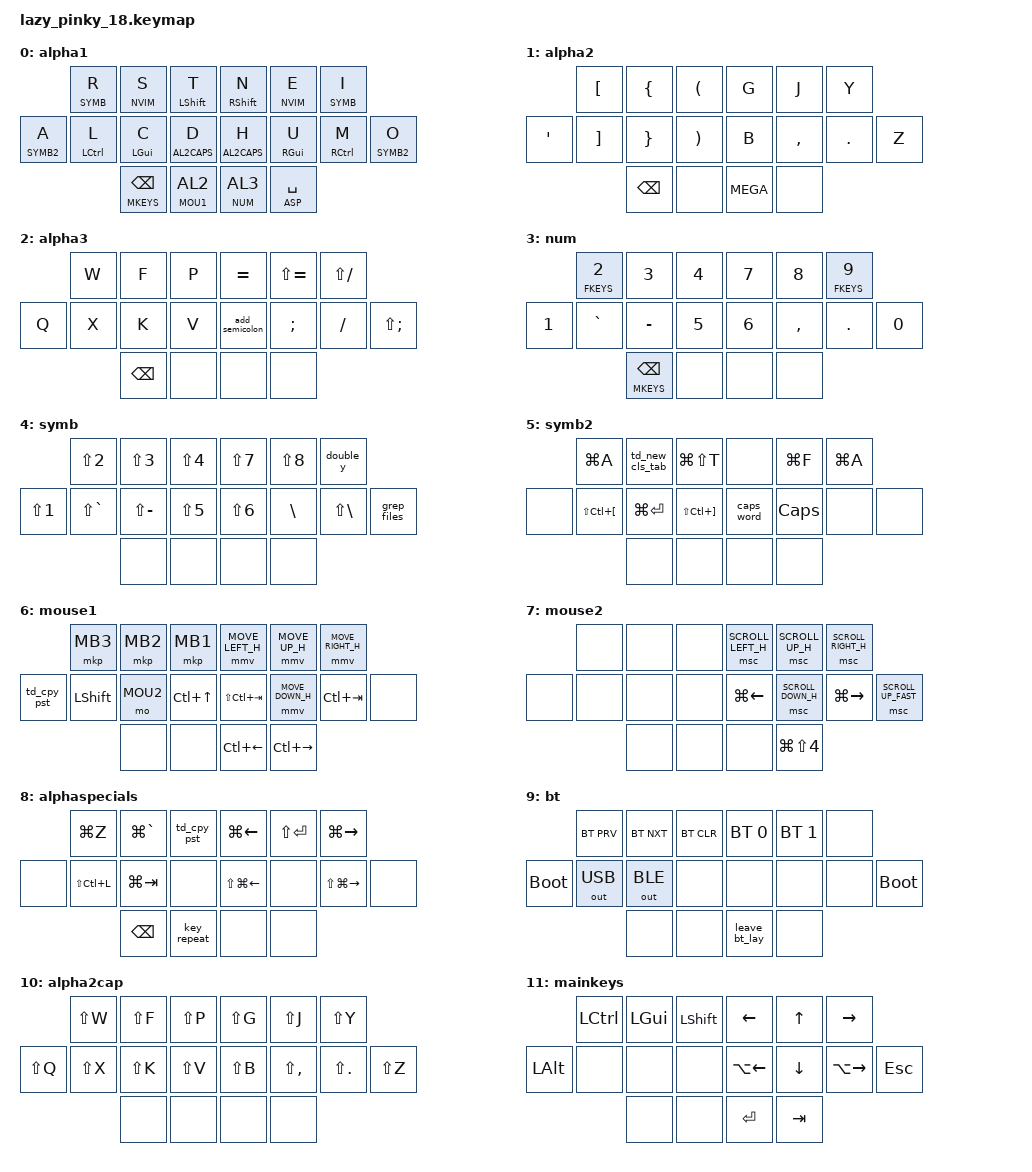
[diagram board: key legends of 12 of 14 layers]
/*
 * Copyright (c) 2020 The ZMK Contributors
 *
 * SPDX-License-Identifier: MIT
 */

#include <behaviors.dtsi>
#include <dt-bindings/zmk/keys.h>
#include <dt-bindings/zmk/bt.h>
#include <dt-bindings/zmk/mouse.h>
#include <dt-bindings/zmk/backlight.h>
#include <dt-bindings/zmk/outputs.h>

#include "mouse.dtsi"

/* Layers */
#define AL1       0
#define AL2       1
#define AL3       2
#define NUM       3
#define SYMB      4
#define SYMB2     5
#define MOU1      6
#define MOU2      7
#define ASP       8
#define BT        9
#define AL2CAPS   10
#define MKEYS     11
#define FKEYS     12
#define NVIM      13

#define MEGA LC(LG(LA(LSHIFT)))

&mt {
    tapping-term-ms = <201>;
    flavor = "tap-preferred";
 };
&sk {
     release-after-ms = <2000>;
     quick-release;
 };

/ { 
    behaviors {
        thu_l: thumb_layers_left {
            compatible = "zmk,behavior-hold-tap";
            label = "THUMB_MODS_L";
            #binding-cells = <2>;
            tapping-term-ms = <150>;
            flavor = "tap-preferred";
            quick-tap-ms = <1>;
            bindings = <&mo>, <&kp>;
        };
        thu_l_2: thumb_layers_left_2 {
            compatible = "zmk,behavior-hold-tap";
            label = "THUMB_MODS_L_2";
            #binding-cells = <2>;
            tapping-term-ms = <150>;
            flavor = "tap-preferred";
            quick-tap-ms = <1>;
            bindings = <&mo>, <&sl>;
            require-prior-idle-ms = <150>;
        };
        thu_r: thumb_layers_right {
            compatible = "zmk,behavior-hold-tap";
            label = "THUMB_MODS_R";
            #binding-cells = <2>;
            tapping-term-ms = <150>;
            flavor = "tap-preferred";
            quick-tap-ms = <1>;
            bindings = <&mo>, <&kp>;
        };
        thu_r_2: thumb_layers_right_2 {
            compatible = "zmk,behavior-hold-tap";
            label = "THUMB_MODS_R_2";
            #binding-cells = <2>;
            tapping-term-ms = <150>;
            flavor = "tap-preferred";
            quick-tap-ms = <1>;
            bindings = <&mo>, <&sl>;
            require-prior-idle-ms = <150>;
        };
        hm_l: homerow_mods_left {
            compatible = "zmk,behavior-hold-tap";
            label = "HOMEROW_MODS_L";
            #binding-cells = <2>;
            tapping-term-ms = <150>;
            quick-tap-ms = <1>;
            flavor = "tap-preferred";
            bindings = <&kp>, <&kp>;
            require-prior-idle-ms = <150>;
        };
        hm_r: homerow_mods_right {
            compatible = "zmk,behavior-hold-tap";
            label = "HOMEROW_MODS_R";
            #binding-cells = <2>;
            tapping-term-ms = <150>;
            quick-tap-ms = <1>;
            flavor = "tap-preferred";
            bindings = <&kp>, <&kp>;
            require-prior-idle-ms = <150>;
        };
        hl_l: homerow_layers_left {
            compatible = "zmk,behavior-hold-tap";
            label = "HOMEROW_LAYERS_L";
            #binding-cells = <2>;
            tapping-term-ms = <150>;
            quick-tap-ms = <1>;
            flavor = "tap-preferred";
            bindings = <&mo>, <&kp>;
            require-prior-idle-ms = <150>;
        };
        hl_r: homerow_layers_right {
            compatible = "zmk,behavior-hold-tap";
            label = "HOMEROW_LAYERS_R";
            #binding-cells = <2>;
            tapping-term-ms = <150>;
            quick-tap-ms = <1>;
            flavor = "tap-preferred";
            bindings = <&mo>, <&kp>;
            require-prior-idle-ms = <150>;
        };

        td_cpy_pst: tapdance_1 {
            compatible = "zmk,behavior-tap-dance";
            label = "TAPDANCE_CP";
            #binding-cells = <0>;
            tapping-term-ms = <200>;
            bindings = <&kp LG(C)>, <&kp LG(V)>;
        };
        td_new_cls_tab: tapdance_2 {
            compatible = "zmk,behavior-tap-dance";
            label = "TAPDANCE_NCT";
            #binding-cells = <0>;
            tapping-term-ms = <200>;
            bindings = <&kp LG(T)>, <&kp LG(W)>;
        };
        td_find_opn_lst: tapdance_3 {
            compatible = "zmk,behavior-tap-dance";
            label = "TAPDANCE_FOL";
            #binding-cells = <0>;
            tapping-term-ms = <200>;
            bindings = <&kp LG(F)>, <&kp LG(LS(T))>;
        };

      alpha2macro: behavior_macro_1 {
        compatible = "zmk,behavior-macro";
        label = "MACRO1";
        #binding-cells = <0>;
        bindings = < &sl AL2 >;
      };
      alpha3macro: behavior_macro_2 {
        compatible = "zmk,behavior-macro";
        label = "MACRO2";
        #binding-cells = <0>;
        bindings = < &sl AL3 >;
      };
      enter_bt_lay: behavior_macro_3 {
        compatible = "zmk,behavior-macro";
        label = "BT backlight ON";
        #binding-cells = <0>;
        bindings =    < &to BT >
                    , < &bl BL_OFF >
                    ;
      };
      leave_bt_lay: behavior_macro_4 {
        compatible = "zmk,behavior-macro";
        label = "BT backlight OFF";
        #binding-cells = <0>;
        bindings =    < &to AL1 >
                    , < &bl BL_ON >
                    ;
      };

      double_y: behavior_macro_7 {
        compatible = "zmk,behavior-macro";
        label = "MACRO7";
        #binding-cells = <0>;
        bindings =    < &kp Y >
                    , < &kp Y >
                    ;
      };
      grep_files: behavior_macro_8 {
        compatible = "zmk,behavior-macro";
        label = "MACRO8";
        #binding-cells = <0>;
        bindings =    < &kp SPC >
                    , < &kp SLASH >
                    ;
      };
      open_down: behavior_macro_9 {
        compatible = "zmk,behavior-macro";
        label = "MACRO9";
        #binding-cells = <0>;
        bindings =    < &kp O >
                    , < &kp DOWN >
                    ;
      };
      lazy_git: behavior_macro_10 {
        compatible = "zmk,behavior-macro";
        label = "MACRO10";
        #binding-cells = <0>;
        bindings =    < &kp SPC >
                    , < &kp G >
                    , < &kp G >
                    ;
      };
      add_semicolon: behavior_macro_11 {
        compatible = "zmk,behavior-macro";
        label = "MACRO11";
        #binding-cells = <0>;
        bindings =    < &kp ESC >
                    , < &kp LS(A) >
                    , < &kp SEMICOLON >
                    , < &kp ESC >
                    ;
      };
    };

//          0    1    2          3      4      5
//     6    7    8    9         10     11     12    13
//              14   15         16     17
    keymap {
    compatible = "zmk,keymap";

    alpha1 { bindings = <
                     &hl_l SYMB  R    &hl_l  NVIM  S        &hm_l    LSHIFT  T      &hm_r    RSHIFT  N    &hl_r  NVIM E     &hl_r SYMB  I
    &hl_l SYMB2 A    &hm_l LCTRL L    &hm_l  LGUI  C        &hl_l    AL2CAPS D      &hl_r    AL2CAPS H    &hm_r  RGUI U     &hm_r RCTRL M   &hl_r SYMB2 O
                                      &thu_l MKEYS BKSP     &thu_l_2 MOU1    AL2    &thu_r_2 NUM     AL3  &thu_r ASP  SPC
    >; };

    alpha2 { bindings = <
                        &kp LEFT_BRACKET   &kp LEFT_BRACE     &kp LEFT_PARENTHESIS    &kp G       &kp J          &kp Y
    &kp SINGLE_QUOTE    &kp RIGHT_BRACKET  &kp RIGHT_BRACE    &kp RIGHT_PARENTHESIS   &kp B       &kp COMMA      &kp DOT    &kp Z 
                                           &kp BKSP           &none                   &kp MEGA    &none
    >; };

    alpha3 { bindings = <
              &kp W     &kp F     &kp P        &kp EQUAL       &kp LS(EQUAL)    &kp LS(SLASH)
    &kp Q     &kp X     &kp K     &kp V        &add_semicolon  &kp SEMICOLON    &kp SLASH        &kp LS(SEMICOLON)
                        &kp BKSP  &none        &none        &none
    >; };

    num { bindings = <
            &hl_r FKEYS N2   &kp N3               &kp N4       &kp N7     &kp N8           &hl_r FKEYS N9
    &kp N1  &kp GRAVE        &kp MINUS            &kp N5       &kp N6     &kp COMMA        &kp DOT         &kp N0
                             &hl_l MKEYS BKSP     &none        &none      &none
    >; };

    symb { bindings = <
                &kp LS(N2)        &kp LS(N3)         &kp LS(N4)     &kp LS(N7)     &kp LS(N8)       &double_y
    &kp LS(N1)  &kp LS(GRAVE)     &kp LS(MINUS)      &kp LS(N5)     &kp LS(N6)     &kp BACKSLASH    &kp LS(BACKSLASH)       &grep_files
                                  &none              &none          &none          &none
    >; };

    symb2 { bindings = <
             &kp LG(A)                  &td_new_cls_tab    &kp LG(LS(T))                &none         &kp LG(F)      &kp LG(A)
    &none    &kp LS(LC(LEFT_BRACKET))   &kp LG(ENTER)      &kp LS(LC(RIGHT_BRACKET))    &caps_word    &kp CAPS       &none      &none
                                        &none              &none                        &none         &none
    >; };

    mouse1 { bindings = <
                  &mkp  MB3    &mkp MB2  &mkp MB1    &mmv MOVE_LEFT_H   &mmv MOVE_UP_H     &mmv MOVE_RIGHT_H
    &td_cpy_pst   &kp LSHIFT   &mo MOU2  &kp LC(UP)  &kp LS(LC(TAB))    &mmv MOVE_DOWN_H   &kp LC(TAB)        &none
                               &none     &none       &kp LC(LEFT)       &kp LC(RIGHT)
    >; };

    mouse2 { bindings = <
           &none   &none   &none   &msc SCROLL_LEFT_H   &msc SCROLL_UP_H     &msc SCROLL_RIGHT_H
    &none  &none   &none   &none   &kp LG(LEFT)         &msc SCROLL_DOWN_H   &kp LG(RIGHT)         &msc SCROLL_UP_FAST
                   &none   &none   &none                &kp LG(LS(N4))  
    >; };

    alphaspecials { bindings = <
            &kp LG(Z)       &kp LG(GRAVE)    &td_cpy_pst      &kp LG(LEFT)         &kp LS(ENTER)     &kp LG(RIGHT)
    &none   &kp LS(LC(L))   &kp LG(TAB)      &none            &kp LS(LG(LEFT))     &none             &kp LS(LG(RIGHT))   &none
                            &kp BKSP         &key_repeat      &none                &none
    >; };

    bt { bindings = <
                    &bt BT_PRV     &bt BT_NXT     &bt BT_CLR      &bt BT_SEL 0     &bt BT_SEL 1    &none
    &bootloader     &out OUT_USB   &out OUT_BLE   &none           &none            &none           &none    &bootloader
                                   &none          &none           &leave_bt_lay    &none
    >; };

    alpha2cap { bindings = <
                &kp LS(W)    &kp LS(F)    &kp LS(P)    &kp LS(G)    &kp LS(J)      &kp LS(Y)
    &kp LS(Q)   &kp LS(X)    &kp LS(K)    &kp LS(V)    &kp LS(B)    &kp LS(COMMA)  &kp LS(DOT)  &kp LS(Z)
                             &none        &none        &none        &none
    >; };

    mainkeys { bindings = <
                 &kp LCTRL    &kp LGUI   &kp LSHIFT        &kp LEFT         &kp UP       &kp RIGHT
    &kp LALT     &none         &none     &none             &kp LA(LEFT)     &kp DOWN     &kp LA(RIGHT)   &kp ESC 
                               &none     &none             &kp ENTER        &kp TAB
    >; };

    fkeys { bindings = <
            &kp F2   &kp F3    &kp F4                    &kp F7    &kp F8     &kp F9
    &kp F1  &none    &none     &kp F5                    &kp F6    &kp F11    &kp F12     &kp F10
                     &none     &enter_bt_lay             &none     &none
    >; };

    nvim_stuff { bindings = <
            &none   &none     &none              &none         &none        &none
    &none   &none   &none     &none              &open_down    &lazy_git    &none   &none
                    &none     &none              &none         &none
    >; };
  };
};

